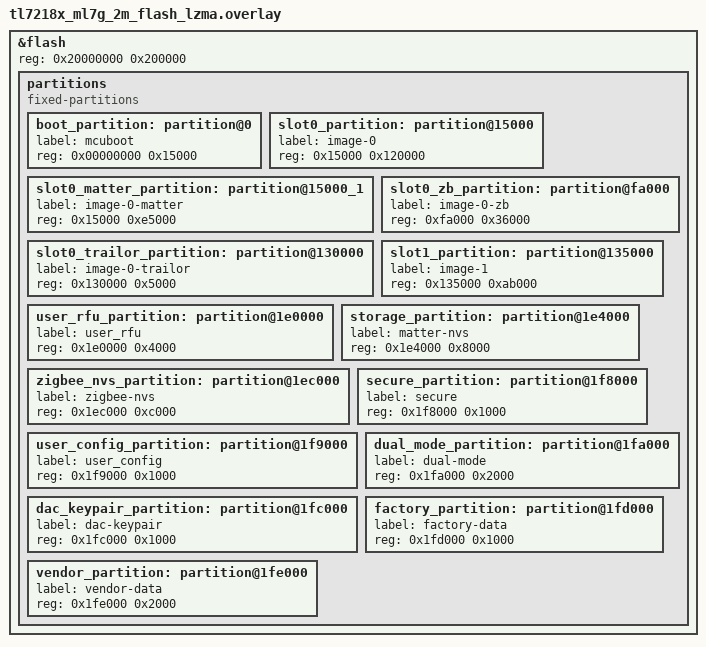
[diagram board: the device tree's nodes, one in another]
&flash {
	reg = <0x20000000 0x200000>;

	/delete-node/ partitions;
	partitions {
		compatible = "fixed-partitions";
		#address-cells = <1>;
		#size-cells = <1>;
		boot_partition: partition@0 {
			label = "mcuboot";
			reg = <0x00000000 0x15000>;
		};
		slot0_partition: partition@15000 {
			label = "image-0";
			reg = <0x15000 0x120000>;
		};
		slot0_matter_partition: partition@15000_1 {
			label = "image-0-matter";
			reg = <0x15000 0xe5000>;
		};
		slot0_zb_partition: partition@fa000 {
			label = "image-0-zb";
			reg = <0xfa000 0x36000>;
		};
		slot0_trailor_partition: partition@130000 {
			label = "image-0-trailor";
			reg = <0x130000 0x5000>;
		};
		slot1_partition: partition@135000 {
			label = "image-1";
			reg = <0x135000 0xab000>;
		};
		user_rfu_partition: partition@1e0000 {
			label = "user_rfu";
			reg = <0x1e0000 0x4000>;
		};
		storage_partition: partition@1e4000 {
			label = "matter-nvs";
			reg = <0x1e4000 0x8000>;
		};
		zigbee_nvs_partition: partition@1ec000 {
			label = "zigbee-nvs";
			reg = <0x1ec000 0xc000>;
		};
		secure_partition: partition@1f8000 {
			label = "secure";
			reg = <0x1f8000 0x1000>;
		};
		user_config_partition: partition@1f9000 {
			label = "user_config";
			reg = <0x1f9000 0x1000>;
		};
		dual_mode_partition: partition@1fa000 {
			label = "dual-mode";
			reg = <0x1fa000 0x2000>;
		};
		dac_keypair_partition: partition@1fc000 {
			label = "dac-keypair";
			reg = <0x1fc000 0x1000>;
		};
		factory_partition: partition@1fd000 {
			label = "factory-data";
			reg = <0x1fd000 0x1000>;
		};
		vendor_partition: partition@1fe000 {
			label = "vendor-data";
			reg = <0x1fe000 0x2000>;
		};
	};
};
